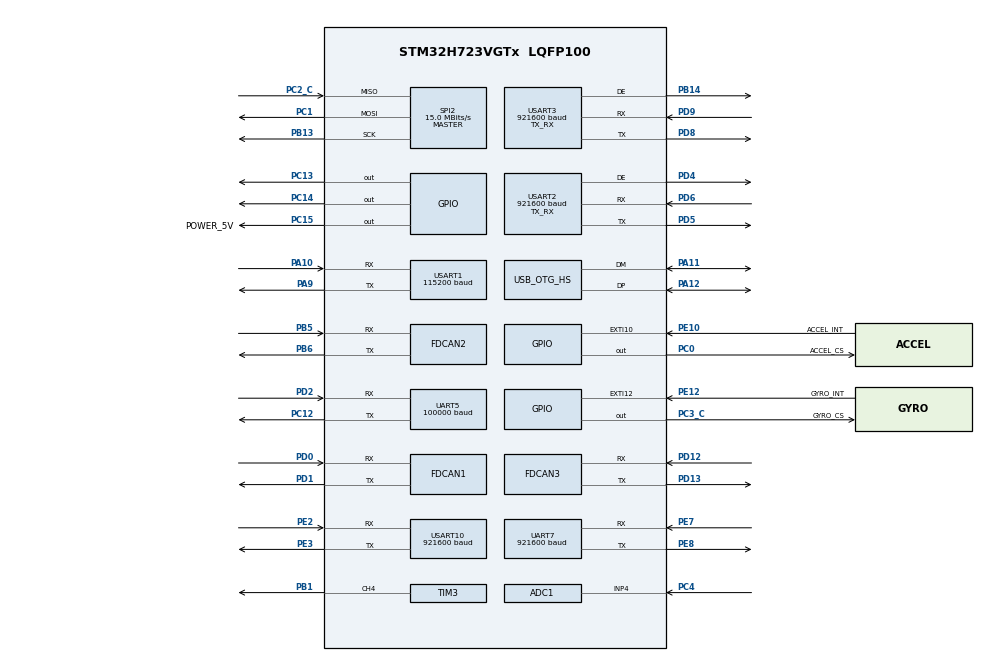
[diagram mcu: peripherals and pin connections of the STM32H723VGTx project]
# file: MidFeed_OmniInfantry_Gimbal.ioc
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ADC1.Channel-2\#ChannelRegularConversion=ADC_CHANNEL_4
ADC1.Channel-3\#ChannelRegularConversion=ADC_CHANNEL_4
ADC1.Channel-IN4=ADC_CHANNEL_4
ADC1.ClockPrescaler=ADC_CLOCK_ASYNC_DIV64
ADC1.ContinuousConvMode=ENABLE
ADC1.ConversionDataManagement=ADC_CONVERSIONDATA_DMA_CIRCULAR
ADC1.DiscontinuousConvMode=DISABLE
ADC1.EOCSelection=ADC_EOC_SINGLE_CONV
ADC1.EnableAnalogWatchDog1=false
ADC1.EnableAnalogWatchDog2=false
ADC1.EnableAnalogWatchDog3=false
ADC1.EnableInjectedConversion=DISABLE
ADC1.EnableRegularConversion=ENABLE
ADC1.ExternalTrigConv=ADC_SOFTWARE_START
ADC1.ExternalTrigConvEdge=ADC_EXTERNALTRIGCONVEDGE_NONE
ADC1.LeftBitShift=ADC_LEFTBITSHIFT_NONE
ADC1.LowPowerAutoWait=DISABLE
ADC1.Mode=ADC_MODE_INDEPENDENT
ADC1.NbrOfConversion=2
ADC1.OffsetNumber-2\#ChannelRegularConversion=ADC_OFFSET_NONE
ADC1.OffsetNumber-3\#ChannelRegularConversion=ADC_OFFSET_NONE
ADC1.OffsetSignedSaturation-2\#ChannelRegularConversion=DISABLE
ADC1.OffsetSignedSaturation-3\#ChannelRegularConversion=DISABLE
ADC1.Overrun=ADC_OVR_DATA_PRESERVED
ADC1.OversamplingMode=DISABLE
ADC1.Rank-2\#ChannelRegularConversion=1
ADC1.Rank-3\#ChannelRegularConversion=2
ADC1.Ratio=1
ADC1.Resolution=ADC_RESOLUTION_16B
ADC1.SamplingTime-2\#ChannelRegularConversion=ADC_SAMPLETIME_32CYCLES_5
ADC1.SamplingTime-3\#ChannelRegularConversion=ADC_SAMPLETIME_1CYCLE_5
ADC1.ScanConvMode=ADC_SCAN_ENABLE
ADC1.master=1
ADC3.Channel-0\#ChannelRegularConversion=ADC_CHANNEL_VBAT
ADC3.Channel-IN=ADC_CHANNEL_VREFINT
ADC3.ClockPrescaler=ADC_CLOCK_ASYNC_DIV64
ADC3.ClockPrescalerADC3=ADC_CLOCK_SYNC_PCLK_DIV4
ADC3.ContinuousConvMode=DISABLE
ADC3.ConversionDataManagement=ADC_CONVERSIONDATA_DR
ADC3.DMAContinuousRequests=DISABLE
ADC3.DataAlign=ADC3_DATAALIGN_RIGHT
ADC3.DiscontinuousConvMode=ENABLE
ADC3.EOCSelection=ADC_EOC_SINGLE_CONV
ADC3.EnableAnalogWatchDog1=false
ADC3.EnableAnalogWatchDog2=false
ADC3.EnableAnalogWatchDog3=false
ADC3.EnableInjectedConversion=DISABLE
ADC3.EnableRegularConversion=ENABLE
ADC3.ExternalTrigConv=ADC_SOFTWARE_START
ADC3.ExternalTrigConvEdge=ADC_EXTERNALTRIGCONVEDGE_NONE
ADC3.LeftBitShift=ADC_LEFTBITSHIFT_NONE
ADC3.LowPowerAutoWait=DISABLE
ADC3.NbrOfConversion=1
ADC3.NbrOfDiscConversion=1
ADC3.OffsetNumber-0\#ChannelRegularConversion=ADC_OFFSET_NONE
ADC3.OffsetSign-0\#ChannelRegularConversion=ADC3_OFFSET_SIGN_NEGATIVE
ADC3.Overrun=ADC_OVR_DATA_PRESERVED
ADC3.OversamplingMode=DISABLE
ADC3.Rank-0\#ChannelRegularConversion=1
ADC3.Ratio=ADC3_OVERSAMPLING_RATIO_2
ADC3.ResolutionADC3=ADC_RESOLUTION_12B
ADC3.SamplingMode=ADC_SAMPLING_MODE_NORMAL
ADC3.SamplingTime-0\#ChannelRegularConversion=ADC3_SAMPLETIME_2CYCLES_5
ADC3.ScanConvMode=ADC_SCAN_DISABLE
CORTEX_M7.default_mode_Activation=1
Dma.ADC1.1.Direction=DMA_PERIPH_TO_MEMORY
Dma.ADC1.1.EventEnable=DISABLE
Dma.ADC1.1.FIFOMode=DMA_FIFOMODE_DISABLE
Dma.ADC1.1.Instance=DMA2_Stream6
Dma.ADC1.1.MemDataAlignment=DMA_MDATAALIGN_HALFWORD
Dma.ADC1.1.MemInc=DMA_MINC_ENABLE
Dma.ADC1.1.Mode=DMA_CIRCULAR
Dma.ADC1.1.PeriphDataAlignment=DMA_PDATAALIGN_HALFWORD
Dma.ADC1.1.PeriphInc=DMA_PINC_DISABLE
Dma.ADC1.1.Polarity=HAL_DMAMUX_REQ_GEN_RISING
Dma.ADC1.1.Priority=DMA_PRIORITY_LOW
Dma.ADC1.1.RequestNumber=1
Dma.ADC1.1.SignalID=NONE
Dma.ADC1.1.SyncEnable=DISABLE
Dma.ADC1.1.SyncPolarity=HAL_DMAMUX_SYNC_NO_EVENT
Dma.ADC1.1.SyncRequestNumber=1
Dma.ADC1.1.SyncSignalID=NONE
Dma.ADC3.8.Direction=DMA_PERIPH_TO_MEMORY
Dma.ADC3.8.EventEnable=DISABLE
Dma.ADC3.8.FIFOMode=DMA_FIFOMODE_DISABLE
Dma.ADC3.8.Instance=DMA1_Stream0
Dma.ADC3.8.MemDataAlignment=DMA_MDATAALIGN_HALFWORD
Dma.ADC3.8.MemInc=DMA_MINC_ENABLE
Dma.ADC3.8.Mode=DMA_CIRCULAR
Dma.ADC3.8.PeriphDataAlignment=DMA_PDATAALIGN_HALFWORD
Dma.ADC3.8.PeriphInc=DMA_PINC_DISABLE
Dma.ADC3.8.Polarity=HAL_DMAMUX_REQ_GEN_RISING
Dma.ADC3.8.Priority=DMA_PRIORITY_LOW
Dma.ADC3.8.RequestNumber=1
Dma.ADC3.8.SignalID=NONE
Dma.ADC3.8.SyncEnable=DISABLE
Dma.ADC3.8.SyncPolarity=HAL_DMAMUX_SYNC_NO_EVENT
Dma.ADC3.8.SyncRequestNumber=1
Dma.ADC3.8.SyncSignalID=NONE
Dma.MEMTOMEM.15.Direction=DMA_MEMORY_TO_MEMORY
Dma.MEMTOMEM.15.EventEnable=DISABLE
Dma.MEMTOMEM.15.FIFOMode=DMA_FIFOMODE_DISABLE
Dma.MEMTOMEM.15.Instance=DMA2_Stream7
Dma.MEMTOMEM.15.MemDataAlignment=DMA_MDATAALIGN_BYTE
Dma.MEMTOMEM.15.MemInc=DMA_MINC_ENABLE
Dma.MEMTOMEM.15.Mode=DMA_NORMAL
Dma.MEMTOMEM.15.PeriphDataAlignment=DMA_PDATAALIGN_BYTE
Dma.MEMTOMEM.15.PeriphInc=DMA_PINC_ENABLE
Dma.MEMTOMEM.15.Polarity=HAL_DMAMUX_REQ_GEN_RISING
Dma.MEMTOMEM.15.Priority=DMA_PRIORITY_LOW
Dma.MEMTOMEM.15.RequestNumber=1
Dma.MEMTOMEM.15.SignalID=NONE
Dma.MEMTOMEM.15.SyncEnable=DISABLE
Dma.MEMTOMEM.15.SyncPolarity=HAL_DMAMUX_SYNC_NO_EVENT
Dma.MEMTOMEM.15.SyncRequestNumber=1
Dma.MEMTOMEM.15.SyncSignalID=NONE
Dma.Request0=UART5_RX
Dma.Request1=ADC1
Dma.Request10=USART2_TX
Dma.Request11=UART7_RX
Dma.Request12=UART7_TX
Dma.Request13=SPI2_RX
Dma.Request14=SPI2_TX
Dma.Request15=MEMTOMEM
Dma.Request2=USART1_RX
Dma.Request3=USART1_TX
Dma.Request4=USART10_RX
Dma.Request5=USART10_TX
Dma.Request6=USART3_RX
Dma.Request7=USART3_TX
Dma.Request8=ADC3
Dma.Request9=USART2_RX
Dma.SPI2_RX.13.Direction=DMA_PERIPH_TO_MEMORY
Dma.SPI2_RX.13.EventEnable=DISABLE
Dma.SPI2_RX.13.FIFOMode=DMA_FIFOMODE_DISABLE
Dma.SPI2_RX.13.Instance=DMA1_Stream1
Dma.SPI2_RX.13.MemDataAlignment=DMA_MDATAALIGN_BYTE
Dma.SPI2_RX.13.MemInc=DMA_MINC_ENABLE
Dma.SPI2_RX.13.Mode=DMA_NORMAL
Dma.SPI2_RX.13.PeriphDataAlignment=DMA_PDATAALIGN_BYTE
Dma.SPI2_RX.13.PeriphInc=DMA_PINC_DISABLE
Dma.SPI2_RX.13.Polarity=HAL_DMAMUX_REQ_GEN_RISING
Dma.SPI2_RX.13.Priority=DMA_PRIORITY_VERY_HIGH
Dma.SPI2_RX.13.RequestNumber=1
Dma.SPI2_RX.13.SignalID=NONE
Dma.SPI2_RX.13.SyncEnable=DISABLE
Dma.SPI2_RX.13.SyncPolarity=HAL_DMAMUX_SYNC_NO_EVENT
Dma.SPI2_RX.13.SyncRequestNumber=1
Dma.SPI2_RX.13.SyncSignalID=NONE
Dma.SPI2_TX.14.Direction=DMA_MEMORY_TO_PERIPH
Dma.SPI2_TX.14.EventEnable=DISABLE
Dma.SPI2_TX.14.FIFOMode=DMA_FIFOMODE_DISABLE
Dma.SPI2_TX.14.Instance=DMA1_Stream2
Dma.SPI2_TX.14.MemDataAlignment=DMA_MDATAALIGN_BYTE
Dma.SPI2_TX.14.MemInc=DMA_MINC_ENABLE
Dma.SPI2_TX.14.Mode=DMA_NORMAL
Dma.SPI2_TX.14.PeriphDataAlignment=DMA_PDATAALIGN_BYTE
Dma.SPI2_TX.14.PeriphInc=DMA_PINC_DISABLE
Dma.SPI2_TX.14.Polarity=HAL_DMAMUX_REQ_GEN_RISING
Dma.SPI2_TX.14.Priority=DMA_PRIORITY_MEDIUM
Dma.SPI2_TX.14.RequestNumber=1
Dma.SPI2_TX.14.SignalID=NONE
Dma.SPI2_TX.14.SyncEnable=DISABLE
Dma.SPI2_TX.14.SyncPolarity=HAL_DMAMUX_SYNC_NO_EVENT
Dma.SPI2_TX.14.SyncRequestNumber=1
Dma.SPI2_TX.14.SyncSignalID=NONE
Dma.UART5_RX.0.Direction=DMA_PERIPH_TO_MEMORY
Dma.UART5_RX.0.EventEnable=DISABLE
Dma.UART5_RX.0.FIFOMode=DMA_FIFOMODE_DISABLE
Dma.UART5_RX.0.Instance=DMA2_Stream3
Dma.UART5_RX.0.MemDataAlignment=DMA_MDATAALIGN_BYTE
Dma.UART5_RX.0.MemInc=DMA_MINC_ENABLE
Dma.UART5_RX.0.Mode=DMA_CIRCULAR
Dma.UART5_RX.0.PeriphDataAlignment=DMA_PDATAALIGN_BYTE
Dma.UART5_RX.0.PeriphInc=DMA_PINC_DISABLE
Dma.UART5_RX.0.Polarity=HAL_DMAMUX_REQ_GEN_RISING
Dma.UART5_RX.0.Priority=DMA_PRIORITY_VERY_HIGH
Dma.UART5_RX.0.RequestNumber=1
Dma.UART5_RX.0.SignalID=NONE
Dma.UART5_RX.0.SyncEnable=DISABLE
Dma.UART5_RX.0.SyncPolarity=HAL_DMAMUX_SYNC_NO_EVENT
Dma.UART5_RX.0.SyncRequestNumber=1
Dma.UART5_RX.0.SyncSignalID=NONE
Dma.UART7_RX.11.Direction=DMA_PERIPH_TO_MEMORY
Dma.UART7_RX.11.EventEnable=DISABLE
Dma.UART7_RX.11.FIFOMode=DMA_FIFOMODE_DISABLE
Dma.UART7_RX.11.Instance=DMA1_Stream3
Dma.UART7_RX.11.MemDataAlignment=DMA_MDATAALIGN_BYTE
Dma.UART7_RX.11.MemInc=DMA_MINC_ENABLE
Dma.UART7_RX.11.Mode=DMA_CIRCULAR
Dma.UART7_RX.11.PeriphDataAlignment=DMA_PDATAALIGN_BYTE
Dma.UART7_RX.11.PeriphInc=DMA_PINC_DISABLE
Dma.UART7_RX.11.Polarity=HAL_DMAMUX_REQ_GEN_RISING
Dma.UART7_RX.11.Priority=DMA_PRIORITY_LOW
Dma.UART7_RX.11.RequestNumber=1
Dma.UART7_RX.11.SignalID=NONE
Dma.UART7_RX.11.SyncEnable=DISABLE
Dma.UART7_RX.11.SyncPolarity=HAL_DMAMUX_SYNC_NO_EVENT
Dma.UART7_RX.11.SyncRequestNumber=1
Dma.UART7_RX.11.SyncSignalID=NONE
Dma.UART7_TX.12.Direction=DMA_MEMORY_TO_PERIPH
Dma.UART7_TX.12.EventEnable=DISABLE
Dma.UART7_TX.12.FIFOMode=DMA_FIFOMODE_DISABLE
Dma.UART7_TX.12.Instance=DMA1_Stream4
Dma.UART7_TX.12.MemDataAlignment=DMA_MDATAALIGN_BYTE
Dma.UART7_TX.12.MemInc=DMA_MINC_ENABLE
Dma.UART7_TX.12.Mode=DMA_NORMAL
Dma.UART7_TX.12.PeriphDataAlignment=DMA_PDATAALIGN_BYTE
Dma.UART7_TX.12.PeriphInc=DMA_PINC_DISABLE
Dma.UART7_TX.12.Polarity=HAL_DMAMUX_REQ_GEN_RISING
Dma.UART7_TX.12.Priority=DMA_PRIORITY_LOW
Dma.UART7_TX.12.RequestNumber=1
Dma.UART7_TX.12.SignalID=NONE
Dma.UART7_TX.12.SyncEnable=DISABLE
Dma.UART7_TX.12.SyncPolarity=HAL_DMAMUX_SYNC_NO_EVENT
Dma.UART7_TX.12.SyncRequestNumber=1
Dma.UART7_TX.12.SyncSignalID=NONE
Dma.USART10_RX.4.Direction=DMA_PERIPH_TO_MEMORY
Dma.USART10_RX.4.EventEnable=DISABLE
Dma.USART10_RX.4.FIFOMode=DMA_FIFOMODE_DISABLE
Dma.USART10_RX.4.Instance=DMA2_Stream4
Dma.USART10_RX.4.MemDataAlignment=DMA_MDATAALIGN_BYTE
Dma.USART10_RX.4.MemInc=DMA_MINC_ENABLE
Dma.USART10_RX.4.Mode=DMA_CIRCULAR
Dma.USART10_RX.4.PeriphDataAlignment=DMA_PDATAALIGN_BYTE
Dma.USART10_RX.4.PeriphInc=DMA_PINC_DISABLE
Dma.USART10_RX.4.Polarity=HAL_DMAMUX_REQ_GEN_RISING
Dma.USART10_RX.4.Priority=DMA_PRIORITY_VERY_HIGH
Dma.USART10_RX.4.RequestNumber=1
Dma.USART10_RX.4.SignalID=NONE
Dma.USART10_RX.4.SyncEnable=DISABLE
Dma.USART10_RX.4.SyncPolarity=HAL_DMAMUX_SYNC_NO_EVENT
Dma.USART10_RX.4.SyncRequestNumber=1
Dma.USART10_RX.4.SyncSignalID=NONE
Dma.USART10_TX.5.Direction=DMA_MEMORY_TO_PERIPH
Dma.USART10_TX.5.EventEnable=DISABLE
Dma.USART10_TX.5.FIFOMode=DMA_FIFOMODE_DISABLE
Dma.USART10_TX.5.Instance=DMA2_Stream5
Dma.USART10_TX.5.MemDataAlignment=DMA_MDATAALIGN_BYTE
Dma.USART10_TX.5.MemInc=DMA_MINC_ENABLE
Dma.USART10_TX.5.Mode=DMA_NORMAL
Dma.USART10_TX.5.PeriphDataAlignment=DMA_PDATAALIGN_BYTE
Dma.USART10_TX.5.PeriphInc=DMA_PINC_DISABLE
Dma.USART10_TX.5.Polarity=HAL_DMAMUX_REQ_GEN_RISING
Dma.USART10_TX.5.Priority=DMA_PRIORITY_VERY_HIGH
Dma.USART10_TX.5.RequestNumber=1
Dma.USART10_TX.5.SignalID=NONE
Dma.USART10_TX.5.SyncEnable=DISABLE
Dma.USART10_TX.5.SyncPolarity=HAL_DMAMUX_SYNC_NO_EVENT
Dma.USART10_TX.5.SyncRequestNumber=1
Dma.USART10_TX.5.SyncSignalID=NONE
Dma.USART1_RX.2.Direction=DMA_PERIPH_TO_MEMORY
Dma.USART1_RX.2.EventEnable=DISABLE
Dma.USART1_RX.2.FIFOMode=DMA_FIFOMODE_DISABLE
Dma.USART1_RX.2.Instance=DMA1_Stream5
Dma.USART1_RX.2.MemDataAlignment=DMA_MDATAALIGN_BYTE
Dma.USART1_RX.2.MemInc=DMA_MINC_ENABLE
Dma.USART1_RX.2.Mode=DMA_NORMAL
Dma.USART1_RX.2.PeriphDataAlignment=DMA_PDATAALIGN_BYTE
Dma.USART1_RX.2.PeriphInc=DMA_PINC_DISABLE
Dma.USART1_RX.2.Polarity=HAL_DMAMUX_REQ_GEN_RISING
Dma.USART1_RX.2.Priority=DMA_PRIORITY_VERY_HIGH
Dma.USART1_RX.2.RequestNumber=1
Dma.USART1_RX.2.SignalID=NONE
Dma.USART1_RX.2.SyncEnable=DISABLE
Dma.USART1_RX.2.SyncPolarity=HAL_DMAMUX_SYNC_NO_EVENT
Dma.USART1_RX.2.SyncRequestNumber=1
Dma.USART1_RX.2.SyncSignalID=NONE
Dma.USART1_TX.3.Direction=DMA_MEMORY_TO_PERIPH
Dma.USART1_TX.3.EventEnable=DISABLE
Dma.USART1_TX.3.FIFOMode=DMA_FIFOMODE_DISABLE
Dma.USART1_TX.3.Instance=DMA1_Stream6
Dma.USART1_TX.3.MemDataAlignment=DMA_MDATAALIGN_BYTE
Dma.USART1_TX.3.MemInc=DMA_MINC_ENABLE
Dma.USART1_TX.3.Mode=DMA_NORMAL
Dma.USART1_TX.3.PeriphDataAlignment=DMA_PDATAALIGN_BYTE
Dma.USART1_TX.3.PeriphInc=DMA_PINC_DISABLE
Dma.USART1_TX.3.Polarity=HAL_DMAMUX_REQ_GEN_RISING
Dma.USART1_TX.3.Priority=DMA_PRIORITY_VERY_HIGH
Dma.USART1_TX.3.RequestNumber=1
Dma.USART1_TX.3.SignalID=NONE
Dma.USART1_TX.3.SyncEnable=DISABLE
Dma.USART1_TX.3.SyncPolarity=HAL_DMAMUX_SYNC_NO_EVENT
Dma.USART1_TX.3.SyncRequestNumber=1
Dma.USART1_TX.3.SyncSignalID=NONE
Dma.USART2_RX.9.Direction=DMA_PERIPH_TO_MEMORY
Dma.USART2_RX.9.EventEnable=DISABLE
Dma.USART2_RX.9.FIFOMode=DMA_FIFOMODE_DISABLE
Dma.USART2_RX.9.Instance=DMA1_Stream7
Dma.USART2_RX.9.MemDataAlignment=DMA_MDATAALIGN_BYTE
Dma.USART2_RX.9.MemInc=DMA_MINC_ENABLE
Dma.USART2_RX.9.Mode=DMA_CIRCULAR
Dma.USART2_RX.9.PeriphDataAlignment=DMA_PDATAALIGN_BYTE
Dma.USART2_RX.9.PeriphInc=DMA_PINC_DISABLE
Dma.USART2_RX.9.Polarity=HAL_DMAMUX_REQ_GEN_RISING
Dma.USART2_RX.9.Priority=DMA_PRIORITY_MEDIUM
Dma.USART2_RX.9.RequestNumber=1
Dma.USART2_RX.9.SignalID=NONE
Dma.USART2_RX.9.SyncEnable=DISABLE
Dma.USART2_RX.9.SyncPolarity=HAL_DMAMUX_SYNC_NO_EVENT
Dma.USART2_RX.9.SyncRequestNumber=1
Dma.USART2_RX.9.SyncSignalID=NONE
Dma.USART2_TX.10.Direction=DMA_MEMORY_TO_PERIPH
Dma.USART2_TX.10.EventEnable=DISABLE
Dma.USART2_TX.10.FIFOMode=DMA_FIFOMODE_DISABLE
Dma.USART2_TX.10.Instance=DMA2_Stream0
Dma.USART2_TX.10.MemDataAlignment=DMA_MDATAALIGN_BYTE
Dma.USART2_TX.10.MemInc=DMA_MINC_ENABLE
Dma.USART2_TX.10.Mode=DMA_NORMAL
Dma.USART2_TX.10.PeriphDataAlignment=DMA_PDATAALIGN_BYTE
Dma.USART2_TX.10.PeriphInc=DMA_PINC_DISABLE
Dma.USART2_TX.10.Polarity=HAL_DMAMUX_REQ_GEN_RISING
Dma.USART2_TX.10.Priority=DMA_PRIORITY_MEDIUM
Dma.USART2_TX.10.RequestNumber=1
Dma.USART2_TX.10.SignalID=NONE
Dma.USART2_TX.10.SyncEnable=DISABLE
Dma.USART2_TX.10.SyncPolarity=HAL_DMAMUX_SYNC_NO_EVENT
Dma.USART2_TX.10.SyncRequestNumber=1
Dma.USART2_TX.10.SyncSignalID=NONE
Dma.USART3_RX.6.Direction=DMA_PERIPH_TO_MEMORY
Dma.USART3_RX.6.EventEnable=DISABLE
Dma.USART3_RX.6.FIFOMode=DMA_FIFOMODE_DISABLE
Dma.USART3_RX.6.Instance=DMA2_Stream1
Dma.USART3_RX.6.MemDataAlignment=DMA_MDATAALIGN_BYTE
Dma.USART3_RX.6.MemInc=DMA_MINC_ENABLE
Dma.USART3_RX.6.Mode=DMA_CIRCULAR
Dma.USART3_RX.6.PeriphDataAlignment=DMA_PDATAALIGN_BYTE
Dma.USART3_RX.6.PeriphInc=DMA_PINC_DISABLE
Dma.USART3_RX.6.Polarity=HAL_DMAMUX_REQ_GEN_RISING
Dma.USART3_RX.6.Priority=DMA_PRIORITY_MEDIUM
Dma.USART3_RX.6.RequestNumber=1
Dma.USART3_RX.6.SignalID=NONE
Dma.USART3_RX.6.SyncEnable=DISABLE
Dma.USART3_RX.6.SyncPolarity=HAL_DMAMUX_SYNC_NO_EVENT
Dma.USART3_RX.6.SyncRequestNumber=1
Dma.USART3_RX.6.SyncSignalID=NONE
Dma.USART3_TX.7.Direction=DMA_MEMORY_TO_PERIPH
Dma.USART3_TX.7.EventEnable=DISABLE
Dma.USART3_TX.7.FIFOMode=DMA_FIFOMODE_DISABLE
Dma.USART3_TX.7.Instance=DMA2_Stream2
Dma.USART3_TX.7.MemDataAlignment=DMA_MDATAALIGN_BYTE
Dma.USART3_TX.7.MemInc=DMA_MINC_ENABLE
Dma.USART3_TX.7.Mode=DMA_NORMAL
Dma.USART3_TX.7.PeriphDataAlignment=DMA_PDATAALIGN_BYTE
Dma.USART3_TX.7.PeriphInc=DMA_PINC_DISABLE
Dma.USART3_TX.7.Polarity=HAL_DMAMUX_REQ_GEN_RISING
Dma.USART3_TX.7.Priority=DMA_PRIORITY_MEDIUM
Dma.USART3_TX.7.RequestNumber=1
Dma.USART3_TX.7.SignalID=NONE
Dma.USART3_TX.7.SyncEnable=DISABLE
Dma.USART3_TX.7.SyncPolarity=HAL_DMAMUX_SYNC_NO_EVENT
Dma.USART3_TX.7.SyncRequestNumber=1
Dma.USART3_TX.7.SyncSignalID=NONE
FDCAN1.AutoRetransmission=DISABLE
FDCAN1.CalculateBaudRateNominal=1000000
FDCAN1.CalculateTimeBitNominal=1000
FDCAN1.CalculateTimeQuantumNominal=25.0
FDCAN1.ClockCalibrationCCU=DISABLE
FDCAN1.DataPrescaler=3
FDCAN1.DataSyncJumpWidth=10
FDCAN1.DataTimeSeg1=29
FDCAN1.DataTimeSeg2=10
FDCAN1.ExtFiltersNbr=0
FDCAN1.FrameFormat=FDCAN_FRAME_CLASSIC
FDCAN1.MessageRAMOffset=0
FDCAN1.Mode=FDCAN_MODE_NORMAL
FDCAN1.NominalPrescaler=3
FDCAN1.NominalSyncJumpWidth=10
FDCAN1.NominalTimeSeg1=29
FDCAN1.NominalTimeSeg2=10
FDCAN1.ProtocolException=ENABLE
FDCAN1.RxBufferSize=FDCAN_DATA_BYTES_8
FDCAN1.RxBuffersNbr=0
FDCAN1.RxFifo0ElmtSize=FDCAN_DATA_BYTES_8
FDCAN1.RxFifo0ElmtsNbr=8
FDCAN1.RxFifo1ElmtSize=FDCAN_DATA_BYTES_8
FDCAN1.RxFifo1ElmtsNbr=8
FDCAN1.StdFiltersNbr=1
FDCAN1.TransmitPause=DISABLE
FDCAN1.TxBuffersNbr=0
FDCAN1.TxElmtSize=FDCAN_DATA_BYTES_8
FDCAN1.TxEventsNbr=0
FDCAN1.TxFifoQueueElmtsNbr=8
FDCAN1.TxFifoQueueMode=FDCAN_TX_FIFO_OPERATION
FDCAN2.AutoRetransmission=DISABLE
FDCAN2.CalculateBaudRateNominal=1000000
FDCAN2.CalculateTimeBitNominal=1000
FDCAN2.CalculateTimeQuantumNominal=25.0
FDCAN2.ClockCalibrationCCU=DISABLE
FDCAN2.DataPrescaler=3
FDCAN2.DataSyncJumpWidth=10
FDCAN2.DataTimeSeg1=29
FDCAN2.DataTimeSeg2=10
FDCAN2.ExtFiltersNbr=0
FDCAN2.FrameFormat=FDCAN_FRAME_CLASSIC
FDCAN2.MessageRAMOffset=853
FDCAN2.Mode=FDCAN_MODE_NORMAL
FDCAN2.NominalPrescaler=3
FDCAN2.NominalSyncJumpWidth=10
FDCAN2.NominalTimeSeg1=29
FDCAN2.NominalTimeSeg2=10
FDCAN2.ProtocolException=ENABLE
FDCAN2.RxBufferSize=FDCAN_DATA_BYTES_8
FDCAN2.RxBuffersNbr=0
FDCAN2.RxFifo0ElmtSize=FDCAN_DATA_BYTES_8
FDCAN2.RxFifo0ElmtsNbr=8
FDCAN2.RxFifo1ElmtSize=FDCAN_DATA_BYTES_8
FDCAN2.RxFifo1ElmtsNbr=8
FDCAN2.StdFiltersNbr=1
FDCAN2.TransmitPause=DISABLE
FDCAN2.TxBuffersNbr=0
FDCAN2.TxElmtSize=FDCAN_DATA_BYTES_8
FDCAN2.TxEventsNbr=0
FDCAN2.TxFifoQueueElmtsNbr=8
FDCAN2.TxFifoQueueMode=FDCAN_TX_FIFO_OPERATION
FDCAN3.AutoRetransmission=DISABLE
FDCAN3.CalculateBaudRateNominal=1000000
FDCAN3.CalculateTimeBitNominal=1000
FDCAN3.CalculateTimeQuantumNominal=25.0
FDCAN3.ClockCalibrationCCU=DISABLE
FDCAN3.DataPrescaler=3
FDCAN3.DataSyncJumpWidth=10
FDCAN3.DataTimeSeg1=29
FDCAN3.DataTimeSeg2=10
FDCAN3.ExtFiltersNbr=0
FDCAN3.FrameFormat=FDCAN_FRAME_CLASSIC
FDCAN3.MessageRAMOffset=1706
FDCAN3.Mode=FDCAN_MODE_NORMAL
FDCAN3.NominalPrescaler=3
FDCAN3.NominalSyncJumpWidth=10
FDCAN3.NominalTimeSeg1=29
FDCAN3.NominalTimeSeg2=10
FDCAN3.ProtocolException=ENABLE
FDCAN3.RxBufferSize=FDCAN_DATA_BYTES_8
FDCAN3.RxBuffersNbr=0
FDCAN3.RxFifo0ElmtSize=FDCAN_DATA_BYTES_8
FDCAN3.RxFifo0ElmtsNbr=8
FDCAN3.RxFifo1ElmtSize=FDCAN_DATA_BYTES_8
FDCAN3.RxFifo1ElmtsNbr=8
FDCAN3.StdFiltersNbr=1
FDCAN3.TransmitPause=DISABLE
FDCAN3.TxBuffersNbr=0
FDCAN3.TxElmtSize=FDCAN_DATA_BYTES_8
FDCAN3.TxEventsNbr=0
FDCAN3.TxFifoQueueElmtsNbr=8
FDCAN3.TxFifoQueueMode=FDCAN_TX_FIFO_OPERATION
FREERTOS.HEAP_NUMBER=4
FREERTOS.INCLUDE_eTaskGetState=0
FREERTOS.INCLUDE_pcTaskGetTaskName=0
FREERTOS.INCLUDE_uxTaskGetStackHighWaterMark=0
FREERTOS.INCLUDE_uxTaskGetStackHighWaterMark2=0
FREERTOS.INCLUDE_uxTaskPriorityGet=1
FREERTOS.INCLUDE_vTaskCleanUpResources=0
FREERTOS.INCLUDE_vTaskDelay=1
FREERTOS.INCLUDE_vTaskDelayUntil=1
FREERTOS.INCLUDE_vTaskDelete=1
FREERTOS.INCLUDE_vTaskPrioritySet=1
FREERTOS.INCLUDE_vTaskSuspend=1
FREERTOS.INCLUDE_xEventGroupSetBitFromISR=0
FREERTOS.INCLUDE_xQueueGetMutexHolder=0
FREERTOS.INCLUDE_xSemaphoreGetMutexHolder=0
FREERTOS.INCLUDE_xTaskAbortDelay=0
FREERTOS.INCLUDE_xTaskGetCurrentTaskHandle=0
FREERTOS.INCLUDE_xTaskGetHandle=0
FREERTOS.INCLUDE_xTaskResumeFromISR=1
FREERTOS.MEMORY_ALLOCATION=2
FREERTOS.Tasks01=Start_INS_Task,2,2048,INS_Task,As weak,NULL,Static,Start_INS_TaskBuffer,Start_INS_TaskControlBlock;Start_Control_Task,1,2048,Control_Task,As weak,NULL,Static,Start_Control_TaskBuffer,Start_Control_TaskControlBlock;Start_CAN_Task,0,2048,CAN_Task,As weak,NULL,Static,Start_CAN_TaskBuffer,Start_CAN_TaskControlBlock;Start_Detect_Task,-1,2048,Detect_Task,As weak,NULL,Static,Start_Detect_TaskBuffer,Start_Detect_TaskControlBlock
FREERTOS.configCHECK_FOR_STACK_OVERFLOW=0
FREERTOS.configENABLE_BACKWARD_COMPATIBILITY=1
FREERTOS.configENABLE_FPU=0
FREERTOS.configGENERATE_RUN_TIME_STATS=0
FREERTOS.configIDLE_SHOULD_YIELD=1
FREERTOS.configLIBRARY_LOWEST_INTERRUPT_PRIORITY=15
FREERTOS.configLIBRARY_MAX_SYSCALL_INTERRUPT_PRIORITY=5
FREERTOS.configMAX_CO_ROUTINE_PRIORITIES=2
FREERTOS.configMAX_PRIORITIES=7
FREERTOS.configMAX_TASK_NAME_LEN=64
FREERTOS.configMINIMAL_STACK_SIZE=2048
FREERTOS.configQUEUE_REGISTRY_SIZE=8
FREERTOS.configRECORD_STACK_HIGH_ADDRESS=0
FREERTOS.configTICK_RATE_HZ=1000
FREERTOS.configTOTAL_HEAP_SIZE=15360
FREERTOS.configUSE_APPLICATION_TASK_TAG=0
FREERTOS.configUSE_COUNTING_SEMAPHORES=0
FREERTOS.configUSE_CO_ROUTINES=0
FREERTOS.configUSE_DAEMON_TASK_STARTUP_HOOK=0
FREERTOS.configUSE_IDLE_HOOK=0
FREERTOS.configUSE_MALLOC_FAILED_HOOK=0
FREERTOS.configUSE_MUTEXES=1
FREERTOS.configUSE_NEWLIB_REENTRANT=1
FREERTOS.configUSE_POSIX_ERRNO=0
FREERTOS.configUSE_PREEMPTION=1
FREERTOS.configUSE_RECURSIVE_MUTEXES=0
FREERTOS.configUSE_STATS_FORMATTING_FUNCTIONS=0
FREERTOS.configUSE_TASK_NOTIFICATIONS=1
FREERTOS.configUSE_TICKLESS_IDLE=0
FREERTOS.configUSE_TICK_HOOK=0
FREERTOS.configUSE_TIMERS=0
FREERTOS.configUSE_TRACE_FACILITY=1
FREERTOS.copyHeapFile=1
Mcu.Family=STM32H7
Mcu.Name=STM32H723VGTx
Mcu.Package=LQFP100
NVIC.DMA1_Stream0_IRQn=true\:5\:0\:false\:false\:true\:true\:false\:true\:true
NVIC.DMA1_Stream1_IRQn=true\:5\:0\:false\:false\:true\:true\:false\:true\:true
NVIC.DMA1_Stream2_IRQn=true\:5\:0\:false\:false\:true\:true\:false\:true\:true
NVIC.DMA1_Stream3_IRQn=true\:5\:0\:false\:false\:true\:true\:false\:true\:true
NVIC.DMA1_Stream4_IRQn=true\:5\:0\:false\:false\:true\:true\:false\:true\:true
NVIC.DMA1_Stream5_IRQn=true\:5\:0\:false\:false\:true\:true\:false\:true\:true
NVIC.DMA1_Stream6_IRQn=true\:5\:0\:false\:false\:true\:true\:false\:true\:true
NVIC.DMA1_Stream7_IRQn=true\:5\:0\:false\:false\:true\:true\:false\:true\:true
NVIC.DMA2_Stream0_IRQn=true\:5\:0\:false\:false\:true\:true\:false\:true\:true
NVIC.DMA2_Stream1_IRQn=true\:5\:0\:false\:false\:true\:true\:false\:true\:true
NVIC.DMA2_Stream2_IRQn=true\:5\:0\:false\:false\:true\:true\:false\:true\:true
NVIC.DMA2_Stream3_IRQn=true\:5\:0\:false\:false\:true\:true\:false\:true\:true
NVIC.DMA2_Stream4_IRQn=true\:5\:0\:false\:false\:true\:true\:false\:true\:true
NVIC.DMA2_Stream5_IRQn=true\:5\:0\:false\:false\:true\:true\:false\:true\:true
NVIC.DMA2_Stream6_IRQn=true\:5\:0\:false\:false\:true\:true\:false\:true\:true
NVIC.DMA2_Stream7_IRQn=true\:5\:0\:false\:false\:true\:true\:false\:true\:true
NVIC.FDCAN1_IT0_IRQn=true\:5\:0\:false\:false\:true\:true\:true\:true\:true
NVIC.FDCAN1_IT1_IRQn=true\:5\:0\:false\:false\:true\:true\:true\:true\:true
NVIC.FDCAN2_IT0_IRQn=true\:5\:0\:false\:false\:true\:true\:true\:true\:true
NVIC.FDCAN2_IT1_IRQn=true\:5\:0\:false\:false\:true\:true\:true\:true\:true
NVIC.FDCAN3_IT0_IRQn=true\:5\:0\:false\:false\:true\:true\:true\:true\:true
NVIC.FDCAN3_IT1_IRQn=true\:5\:0\:false\:false\:true\:true\:true\:true\:true
NVIC.OTG_HS_IRQn=true\:5\:0\:false\:false\:true\:true\:true\:true\:true
NVIC.PriorityGroup=NVIC_PRIORITYGROUP_4
NVIC.SPI2_IRQn=true\:5\:0\:true\:false\:true\:true\:false\:true\:true
NVIC.TIM2_IRQn=true\:15\:0\:false\:false\:true\:false\:true\:true\:true
NVIC.TimeBase=TIM2_IRQn
NVIC.TimeBaseIP=TIM2
NVIC.UART5_IRQn=true\:5\:0\:false\:false\:true\:true\:true\:true\:true
NVIC.UART7_IRQn=true\:5\:0\:false\:false\:true\:true\:true\:true\:true
NVIC.USART10_IRQn=true\:5\:0\:false\:false\:true\:true\:true\:true\:true
NVIC.USART1_IRQn=true\:5\:0\:false\:false\:true\:true\:true\:true\:true
NVIC.USART2_IRQn=true\:5\:0\:false\:false\:true\:true\:true\:true\:true
NVIC.USART3_IRQn=true\:5\:0\:false\:false\:true\:true\:true\:true\:true
PA10.Mode=Asynchronous
PA10.Signal=USART1_RX
PA11.Mode=Device_Only_FS
PA11.Signal=USB_OTG_HS_DM
PA12.Mode=Device_Only_FS
PA12.Signal=USB_OTG_HS_DP
PA13(JTMS/SWDIO).Mode=Serial_Wire
PA13(JTMS/SWDIO).Signal=DEBUG_JTMS-SWDIO
PA14(JTCK/SWCLK).Mode=Serial_Wire
PA14(JTCK/SWCLK).Signal=DEBUG_JTCK-SWCLK
PA9.Mode=Asynchronous
PA9.Signal=USART1_TX
PB1.Signal=S_TIM3_CH4
PB13.GPIO_Speed=GPIO_SPEED_FREQ_VERY_HIGH
PB13.Mode=Full_Duplex_Master
PB13.Signal=SPI2_SCK
PB14.Mode=Hardware Flow Control (RS485)
PB14.Signal=USART3_DE
PB5.Mode=FDCAN_Activate
PB5.Signal=FDCAN2_RX
PB6.GPIO_FM6=__NULL
PB6.Mode=FDCAN_Activate
PB6.Signal=FDCAN2_TX
PC0.GPIO_Label=ACCEL_CS
PC0.GPIO_PuPd=GPIO_NOPULL
PC0.GPIO_Speed=GPIO_SPEED_FREQ_MEDIUM
PC0.PinState=GPIO_PIN_SET
PC0.Signal=GPIO_Output
PC1.GPIO_Speed=GPIO_SPEED_FREQ_VERY_HIGH
PC1.Mode=Full_Duplex_Master
PC1.Signal=SPI2_MOSI
PC12.Mode=Asynchronous
PC12.Signal=UART5_TX
PC13.PinState=GPIO_PIN_RESET
PC13.Signal=GPIO_Output
PC14-OSC32_IN.Signal=GPIO_Output
PC15-OSC32_OUT.GPIO_Label=POWER_5V
PC15-OSC32_OUT.PinState=GPIO_PIN_SET
PC15-OSC32_OUT.Signal=GPIO_Output
PC2_C.GPIO_Speed=GPIO_SPEED_FREQ_VERY_HIGH
PC2_C.Mode=Full_Duplex_Master
PC2_C.Signal=SPI2_MISO
PC3_C.GPIO_Label=GYRO_CS
PC3_C.GPIO_PuPd=GPIO_NOPULL
PC3_C.GPIO_Speed=GPIO_SPEED_FREQ_MEDIUM
PC3_C.PinState=GPIO_PIN_SET
PC3_C.Signal=GPIO_Output
PC4.Signal=ADCx_INP4
PD0.Mode=FDCAN_Activate
PD0.Signal=FDCAN1_RX
PD1.Mode=FDCAN_Activate
PD1.Signal=FDCAN1_TX
PD12.Mode=FDCAN_Activate
PD12.Signal=FDCAN3_RX
PD13.Mode=FDCAN_Activate
PD13.Signal=FDCAN3_TX
PD2.GPIO_Speed=GPIO_SPEED_FREQ_VERY_HIGH
PD2.Mode=Asynchronous
PD2.Signal=UART5_RX
PD4.Mode=Hardware Flow Control (RS485)
PD4.Signal=USART2_DE
PD5.Mode=Asynchronous
PD5.Signal=USART2_TX
PD6.Mode=Asynchronous
PD6.Signal=USART2_RX
PD8.Mode=Asynchronous
PD8.Signal=USART3_TX
PD9.Mode=Asynchronous
PD9.Signal=USART3_RX
PE10.GPIO_Label=ACCEL_INT
PE10.GPIO_PuPd=GPIO_NOPULL
PE10.Signal=GPXTI10
PE12.GPIO_Label=GYRO_INT
PE12.GPIO_PuPd=GPIO_NOPULL
PE12.Signal=GPXTI12
PE2.Mode=Asynchronous
PE2.Signal=USART10_RX
PE3.Mode=Asynchronous
PE3.Signal=USART10_TX
PE7.Mode=Asynchronous
PE7.Signal=UART7_RX
PE8.Mode=Asynchronous
PE8.Signal=UART7_TX
PH0-OSC_IN.Mode=HSE-External-Oscillator
PH0-OSC_IN.Signal=RCC_OSC_IN
PH1-OSC_OUT.Mode=HSE-External-Oscillator
PH1-OSC_OUT.Signal=RCC_OSC_OUT
ProjectManager.HeapSize=0x2000
ProjectManager.StackSize=0x4000
ProjectManager.TargetToolchain=STM32CubeIDE
RCC.ADCFreq_Value=96000000
RCC.APB1Freq_Value=120000000
RCC.APB2Freq_Value=120000000
RCC.APB3Freq_Value=120000000
RCC.APB4Freq_Value=120000000
RCC.CortexFreq_Value=480000000
RCC.D1PPRE=RCC_APB3_DIV2
RCC.D2PPRE1=RCC_APB1_DIV2
RCC.D2PPRE2=RCC_APB2_DIV2
RCC.D3PPRE=RCC_APB4_DIV2
RCC.DIVM1=2
RCC.DIVM2=2
RCC.DIVN1=40
RCC.DIVN2=32
RCC.DIVP1=1
RCC.DIVP2=4
RCC.DIVQ1=4
RCC.HCLKFreq_Value=240000000
RCC.HPRE=RCC_HCLK_DIV2
RCC.HSE_VALUE=24000000
RCC.PLL2FRACN=0
RCC.PLL2_VCO_SEL-AdvancedSettings=RCC_PLL2VCOMEDIUM
RCC.PLL3_VCO_SEL-AdvancedSettings=RCC_PLL3VCOWIDE
RCC.PLLFRACN=0
RCC.PLLSourceVirtual=RCC_PLLSOURCE_HSE
RCC.SYSCLKFreq_VALUE=480000000
RCC.SYSCLKSource=RCC_SYSCLKSOURCE_PLLCLK
RCC.USBFreq_Value=120000000
SH.ADCx_INP4.0=ADC1_INP4,IN4-Single-Ended
SH.S_TIM3_CH4.0=TIM3_CH4,PWM Generation4 CH4
SPI2.BaudRatePrescaler=SPI_BAUDRATEPRESCALER_8
SPI2.CLKPhase=SPI_PHASE_2EDGE
SPI2.CLKPolarity=SPI_POLARITY_HIGH
SPI2.CRCCalculation=SPI_CRCCALCULATION_DISABLE
SPI2.CalculateBaudRate=15.0 MBits/s
SPI2.DataSize=SPI_DATASIZE_8BIT
SPI2.Direction=SPI_DIRECTION_2LINES
SPI2.FifoThreshold=SPI_FIFO_THRESHOLD_01DATA
SPI2.FirstBit=SPI_FIRSTBIT_MSB
SPI2.IOSwap=SPI_IO_SWAP_DISABLE
SPI2.MasterInterDataIdleness=SPI_MASTER_INTERDATA_IDLENESS_00CYCLE
SPI2.MasterKeepIOState=SPI_MASTER_KEEP_IO_STATE_DISABLE
SPI2.MasterReceiverAutoSusp=SPI_MASTER_RX_AUTOSUSP_DISABLE
SPI2.MasterSSIdleness=SPI_MASTER_SS_IDLENESS_00CYCLE
SPI2.Mode=SPI_MODE_MASTER
SPI2.NSS=SPI_NSS_SOFT
SPI2.NSSPMode=SPI_NSS_PULSE_DISABLE
SPI2.NSSPolarity=SPI_NSS_POLARITY_LOW
SPI2.RxCRCInitializationPattern=SPI_CRC_INITIALIZATION_ALL_ZERO_PATTERN
SPI2.TIMode=SPI_TIMODE_DISABLE
SPI2.TxCRCInitializationPattern=SPI_CRC_INITIALIZATION_ALL_ZERO_PATTERN
SPI2.VirtualType=VM_MASTER
TIM3.AutoReloadPreload=TIM_AUTORELOAD_PRELOAD_ENABLE
TIM3.Channel-PWM\ Generation4\ CH4=TIM_CHANNEL_4
TIM3.ClearInputSource=TIM_CLEARINPUTSOURCE_NONE
TIM3.ClockDivision=TIM_CLOCKDIVISION_DIV1
TIM3.CounterMode=TIM_COUNTERMODE_UP
TIM3.OC4Preload_PWM=ENABLE
TIM3.OCFastMode_PWM-PWM\ Generation4\ CH4=TIM_OCFAST_DISABLE
TIM3.OCMode_PWM-PWM\ Generation4\ CH4=TIM_OCMODE_PWM1
TIM3.OCPolarity_4=TIM_OCPOLARITY_HIGH
TIM3.Period=20000
TIM3.Prescaler=80-1
TIM3.Pulse-PWM\ Generation4\ CH4=0
TIM3.TIM_MasterOutputTrigger=TIM_TRGO_RESET
TIM3.TIM_MasterSlaveMode=TIM_MASTERSLAVEMODE_DISABLE
UART5.AutoBaudRateEnableParam=UART_ADVFEATURE_AUTOBAUDRATE_DISABLE
UART5.BaudRate=100000
UART5.ClockPrescaler=PRESCALER_DIV1
UART5.DMADisableonRxErrorParam=UART_ADVFEATURE_DMA_ENABLEONRXERROR
UART5.DataInvertParam=UART_ADVFEATURE_DATAINV_DISABLE
UART5.FIFOMode=FIFOMODE_DISABLE
UART5.MSBFirstParam=UART_ADVFEATURE_MSBFIRST_DISABLE
UART5.Mode=MODE_TX_RX
UART5.OneBitSampling=UART_ONE_BIT_SAMPLE_DISABLE
UART5.OverSampling=UART_OVERSAMPLING_16
UART5.OverrunDisableParam=UART_ADVFEATURE_OVERRUN_ENABLE
UART5.Parity=PARITY_EVEN
UART5.RXFIFOThreshold=RXFIFO_THRESHOLD_1EIGHTHFULL
UART5.RxPinLevelInvertParam=UART_ADVFEATURE_RXINV_DISABLE
UART5.StopBits=UART_STOPBITS_2
UART5.SwapParam=UART_ADVFEATURE_SWAP_DISABLE
UART5.TXFIFOThreshold=TXFIFO_THRESHOLD_1EIGHTHFULL
UART5.TxPinLevelInvertParam=UART_ADVFEATURE_TXINV_DISABLE
UART5.WordLength=WORDLENGTH_9B
UART7.AutoBaudRateEnableParam=UART_ADVFEATURE_AUTOBAUDRATE_DISABLE
UART7.BaudRate=921600
UART7.ClockPrescaler=PRESCALER_DIV1
UART7.DMADisableonRxErrorParam=UART_ADVFEATURE_DMA_ENABLEONRXERROR
UART7.DataInvertParam=UART_ADVFEATURE_DATAINV_DISABLE
UART7.FIFOMode=FIFOMODE_DISABLE
UART7.MSBFirstParam=UART_ADVFEATURE_MSBFIRST_DISABLE
UART7.Mode=MODE_TX_RX
UART7.OneBitSampling=UART_ONE_BIT_SAMPLE_DISABLE
UART7.OverSampling=UART_OVERSAMPLING_16
UART7.OverrunDisableParam=UART_ADVFEATURE_OVERRUN_ENABLE
UART7.Parity=PARITY_NONE
UART7.RXFIFOThreshold=RXFIFO_THRESHOLD_1EIGHTHFULL
UART7.RxPinLevelInvertParam=UART_ADVFEATURE_RXINV_DISABLE
UART7.StopBits=UART_STOPBITS_1
UART7.SwapParam=UART_ADVFEATURE_SWAP_DISABLE
UART7.TXFIFOThreshold=TXFIFO_THRESHOLD_1EIGHTHFULL
UART7.TxPinLevelInvertParam=UART_ADVFEATURE_TXINV_DISABLE
UART7.WordLength=WORDLENGTH_8B
USART1.AutoBaudRateEnableParam=UART_ADVFEATURE_AUTOBAUDRATE_DISABLE
USART1.BaudRate=115200
USART1.ClockPrescaler=PRESCALER_DIV1
USART1.DMADisableonRxErrorParam=ADVFEATURE_DMA_ENABLEONRXERROR
USART1.DataInvertParam=ADVFEATURE_DATAINV_DISABLE
USART1.FIFOMode=FIFOMODE_DISABLE
USART1.MSBFirstParam=ADVFEATURE_MSBFIRST_DISABLE
USART1.Mode=MODE_TX_RX
USART1.OneBitSampling=UART_ONE_BIT_SAMPLE_DISABLE
USART1.OverSampling=UART_OVERSAMPLING_16
USART1.OverrunDisableParam=ADVFEATURE_OVERRUN_ENABLE
USART1.Parity=PARITY_NONE
USART1.RXFIFOThreshold=RXFIFO_THRESHOLD_1EIGHTHFULL
USART1.RxPinLevelInvertParam=ADVFEATURE_RXINV_DISABLE
USART1.StopBits=STOPBITS_1
USART1.SwapParam=ADVFEATURE_SWAP_DISABLE
USART1.TXFIFOThreshold=TXFIFO_THRESHOLD_1EIGHTHFULL
USART1.TxPinLevelInvertParam=ADVFEATURE_TXINV_DISABLE
USART1.VirtualMode-Asynchronous=VM_ASYNC
USART1.WordLength=WORDLENGTH_8B
USART10.AutoBaudRateEnableParam=UART_ADVFEATURE_AUTOBAUDRATE_DISABLE
USART10.BaudRate=921600
USART10.ClockPrescaler=PRESCALER_DIV1
USART10.DMADisableonRxErrorParam=ADVFEATURE_DMA_ENABLEONRXERROR
USART10.DataInvertParam=ADVFEATURE_DATAINV_DISABLE
USART10.FIFOMode=FIFOMODE_DISABLE
USART10.MSBFirstParam=ADVFEATURE_MSBFIRST_DISABLE
USART10.Mode=MODE_TX_RX
USART10.OneBitSampling=UART_ONE_BIT_SAMPLE_DISABLE
USART10.OverSampling=UART_OVERSAMPLING_16
USART10.OverrunDisableParam=ADVFEATURE_OVERRUN_ENABLE
USART10.Parity=PARITY_NONE
USART10.RXFIFOThreshold=RXFIFO_THRESHOLD_1EIGHTHFULL
USART10.RxPinLevelInvertParam=ADVFEATURE_RXINV_DISABLE
USART10.StopBits=STOPBITS_1
USART10.SwapParam=ADVFEATURE_SWAP_DISABLE
USART10.TXFIFOThreshold=TXFIFO_THRESHOLD_1EIGHTHFULL
USART10.TxPinLevelInvertParam=ADVFEATURE_TXINV_DISABLE
USART10.VirtualMode=VM_ASYNC
USART10.WordLength=WORDLENGTH_8B
USART2.AutoBaudRateEnableParam=UART_ADVFEATURE_AUTOBAUDRATE_DISABLE
USART2.BaudRate=921600
USART2.ClockPrescaler=PRESCALER_DIV1
USART2.DMADisableonRxErrorParam=ADVFEATURE_DMA_ENABLEONRXERROR
USART2.DataInvertParam=ADVFEATURE_DATAINV_DISABLE
USART2.FIFOMode=FIFOMODE_DISABLE
USART2.MSBFirstParam=ADVFEATURE_MSBFIRST_DISABLE
USART2.Mode=MODE_TX_RX
USART2.OneBitSampling=UART_ONE_BIT_SAMPLE_DISABLE
USART2.OverSampling=UART_OVERSAMPLING_8
USART2.OverrunDisableParam=ADVFEATURE_OVERRUN_ENABLE
USART2.Parity=PARITY_NONE
USART2.RXFIFOThreshold=RXFIFO_THRESHOLD_1EIGHTHFULL
USART2.RxPinLevelInvertParam=ADVFEATURE_RXINV_DISABLE
USART2.StopBits=STOPBITS_1
USART2.SwapParam=ADVFEATURE_SWAP_DISABLE
USART2.TXFIFOThreshold=TXFIFO_THRESHOLD_1EIGHTHFULL
USART2.TxPinLevelInvertParam=ADVFEATURE_TXINV_DISABLE
USART2.UART_DEAssertionTime=0
USART2.UART_DEDeassertionTime=0
USART2.UART_DEPolarity=UART_DE_POLARITY_HIGH
USART2.VirtualMode-Asynchronous=VM_ASYNC
USART2.VirtualMode-Hardware\ Flow\ Control\ (RS485)=VM_ASYNC
USART2.WordLength=WORDLENGTH_8B
USART3.AutoBaudRateEnableParam=UART_ADVFEATURE_AUTOBAUDRATE_DISABLE
USART3.BaudRate=921600
USART3.ClockPrescaler=PRESCALER_DIV1
USART3.DMADisableonRxErrorParam=ADVFEATURE_DMA_ENABLEONRXERROR
USART3.DataInvertParam=ADVFEATURE_DATAINV_DISABLE
USART3.FIFOMode=FIFOMODE_DISABLE
USART3.MSBFirstParam=ADVFEATURE_MSBFIRST_DISABLE
USART3.Mode=MODE_TX_RX
USART3.OneBitSampling=UART_ONE_BIT_SAMPLE_DISABLE
USART3.OverSampling=UART_OVERSAMPLING_8
USART3.OverrunDisableParam=ADVFEATURE_OVERRUN_ENABLE
USART3.Parity=PARITY_NONE
USART3.RXFIFOThreshold=RXFIFO_THRESHOLD_1EIGHTHFULL
USART3.RxPinLevelInvertParam=ADVFEATURE_RXINV_DISABLE
USART3.StopBits=STOPBITS_1
USART3.SwapParam=ADVFEATURE_SWAP_DISABLE
USART3.TXFIFOThreshold=TXFIFO_THRESHOLD_1EIGHTHFULL
USART3.TxPinLevelInvertParam=ADVFEATURE_TXINV_DISABLE
USART3.UART_DEAssertionTime=0
USART3.UART_DEDeassertionTime=0
USART3.UART_DEPolarity=UART_DE_POLARITY_HIGH
USART3.VirtualMode-Asynchronous=VM_ASYNC
USART3.VirtualMode-Hardware\ Flow\ Control\ (RS485)=VM_ASYNC
USART3.WordLength=WORDLENGTH_8B
USB_DEVICE.APP_RX_DATA_SIZE=2048
USB_DEVICE.APP_TX_DATA_SIZE=2048
USB_DEVICE.CLASS_NAME_HS=CDC
USB_DEVICE.CONFIGURATION_STRING_CDC_HS=CDC Config
USB_DEVICE.INTERFACE_STRING_CDC_HS=CDC Interface
USB_DEVICE.LANGID_STRING=1033
USB_DEVICE.MANUFACTURER_STRING=STMicroelectronics
USB_DEVICE.PID_CDC_HS=22336
USB_DEVICE.PRODUCT_STRING_CDC_HS=STM32 Virtual ComPort
USB_DEVICE.USBD_DEBUG_LEVEL=0
USB_DEVICE.USBD_LPM_ENABLED=1
USB_DEVICE.USBD_MAX_NUM_CONFIGURATION=1
USB_DEVICE.USBD_MAX_NUM_INTERFACES=1
USB_DEVICE.USBD_MAX_STR_DESC_SIZ=512
USB_DEVICE.USBD_SELF_POWERED=1
USB_DEVICE.VID=1155
USB_DEVICE.VirtualMode=Cdc
USB_DEVICE.VirtualModeHS=Cdc_HS
USB_OTG_HS.VirtualMode-Device_Only_FS=Device_Only_FS
USB_OTG_HS.dma_enable-Device_Only_FS=DISABLE
USB_OTG_HS.low_power_enable-Device_Only_FS=DISABLE
USB_OTG_HS.lpm_enable-Device_Only_FS=DISABLE
USB_OTG_HS.phy_itface-Device_Only_FS=USB_OTG_EMBEDDED_PHY
USB_OTG_HS.use_dedicated_ep1-Device_Only_FS=DISABLE
VP_ADC3_TempSens_Input.Mode=IN-TempSens
VP_ADC3_Vbat_Input.Mode=IN-Vbat
VP_ADC3_Vref_Input.Mode=IN-Vrefint
VP_FREERTOS_VS_CMSIS_V1.Mode=CMSIS_V1
VP_MEMORYMAP_VS_MEMORYMAP.Mode=CurAppReg
VP_SYS_VS_tim2.Mode=TIM2
VP_USB_DEVICE_VS_USB_DEVICE_CDC_HS.Mode=CDC_HS
board=custom

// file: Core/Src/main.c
/* USER CODE BEGIN Header */
/**
  ******************************************************************************
  * @file           : main.c
  * @brief          : Main program body
  ******************************************************************************
  * @attention
  *
  * Copyright (c) 2025 STMicroelectronics.
  * All rights reserved.
  *
  * This software is licensed under terms that can be found in the LICENSE file
  * in the root directory of this software component.
  * If no LICENSE file comes with this software, it is provided AS-IS.
  *
  ******************************************************************************
  */
/* USER CODE END Header */
#include "main.h"
#include "cmsis_os.h"
#include "adc.h"
#include "dma.h"
#include "fdcan.h"
#include "spi.h"
#include "tim.h"
#include "usart.h"
#include "usb_device.h"
#include "gpio.h"

/* USER CODE BEGIN Includes */
#include "sum_init.h"
/* USER CODE END Includes */

void SystemClock_Config(void);
void PeriphCommonClock_Config(void);
static void MPU_Config(void);
void MX_FREERTOS_Init(void);

int main(void)
{

  /* MPU Configuration--------------------------------------------------------*/
  MPU_Config();

  /* MCU Configuration--------------------------------------------------------*/

  /* Reset of all peripherals, Initializes the Flash interface and the Systick. */
  HAL_Init();

  /* Configure the system clock */
  SystemClock_Config();

  /* Configure the peripherals common clocks */
  PeriphCommonClock_Config();

  /* Initialize all configured peripherals */
  MX_GPIO_Init();
  MX_DMA_Init();
  MX_FDCAN1_Init();
  MX_FDCAN2_Init();
  MX_UART5_Init();
  MX_SPI2_Init();
  MX_TIM3_Init();
  MX_UART7_Init();
  MX_USART1_UART_Init();
  MX_USART2_UART_Init();
  MX_USART3_UART_Init();
  MX_USART10_UART_Init();
  MX_FDCAN3_Init();
  MX_ADC3_Init();
  MX_ADC1_Init();
  /* USER CODE BEGIN 2 */
  Sum_Init();
  /* USER CODE END 2 */

  /* Call init function for freertos objects (in cmsis_os2.c) */
  MX_FREERTOS_Init();

  /* Start scheduler */
  osKernelStart();

  /* We should never get here as control is now taken by the scheduler */

  /* Infinite loop */
  while (1)
  {

  }
}

void SystemClock_Config(void)
{
  RCC_OscInitTypeDef RCC_OscInitStruct = {0};
  RCC_ClkInitTypeDef RCC_ClkInitStruct = {0};

  /** Supply configuration update enable
  */
  HAL_PWREx_ConfigSupply(PWR_LDO_SUPPLY);

  /** Configure the main internal regulator output voltage
  */
  __HAL_PWR_VOLTAGESCALING_CONFIG(PWR_REGULATOR_VOLTAGE_SCALE0);

  while(!__HAL_PWR_GET_FLAG(PWR_FLAG_VOSRDY)) {}

  /** Initializes the RCC Oscillators according to the specified parameters
  * in the RCC_OscInitTypeDef structure.
  */
  RCC_OscInitStruct.OscillatorType = RCC_OSCILLATORTYPE_HSE;
  RCC_OscInitStruct.HSEState = RCC_HSE_ON;
  RCC_OscInitStruct.PLL.PLLState = RCC_PLL_ON;
  RCC_OscInitStruct.PLL.PLLSource = RCC_PLLSOURCE_HSE;
  RCC_OscInitStruct.PLL.PLLM = 2;
  RCC_OscInitStruct.PLL.PLLN = 40;
  RCC_OscInitStruct.PLL.PLLP = 1;
  RCC_OscInitStruct.PLL.PLLQ = 4;
  RCC_OscInitStruct.PLL.PLLR = 2;
  RCC_OscInitStruct.PLL.PLLRGE = RCC_PLL1VCIRANGE_3;
  RCC_OscInitStruct.PLL.PLLVCOSEL = RCC_PLL1VCOWIDE;
  RCC_OscInitStruct.PLL.PLLFRACN = 0;
  if (HAL_RCC_OscConfig(&RCC_OscInitStruct) != HAL_OK)
  {
    Error_Handler();
  }

  /** Initializes the CPU, AHB and APB buses clocks
  */
  RCC_ClkInitStruct.ClockType = RCC_CLOCKTYPE_HCLK|RCC_CLOCKTYPE_SYSCLK
                              |RCC_CLOCKTYPE_PCLK1|RCC_CLOCKTYPE_PCLK2
                              |RCC_CLOCKTYPE_D3PCLK1|RCC_CLOCKTYPE_D1PCLK1;
  RCC_ClkInitStruct.SYSCLKSource = RCC_SYSCLKSOURCE_PLLCLK;
  RCC_ClkInitStruct.SYSCLKDivider = RCC_SYSCLK_DIV1;
  RCC_ClkInitStruct.AHBCLKDivider = RCC_HCLK_DIV2;
  RCC_ClkInitStruct.APB3CLKDivider = RCC_APB3_DIV2;
  RCC_ClkInitStruct.APB1CLKDivider = RCC_APB1_DIV2;
  RCC_ClkInitStruct.APB2CLKDivider = RCC_APB2_DIV2;
  RCC_ClkInitStruct.APB4CLKDivider = RCC_APB4_DIV2;

  if (HAL_RCC_ClockConfig(&RCC_ClkInitStruct, FLASH_LATENCY_3) != HAL_OK)
  {
    Error_Handler();
  }
}

void PeriphCommonClock_Config(void)
{
  RCC_PeriphCLKInitTypeDef PeriphClkInitStruct = {0};

  /** Initializes the peripherals clock
  */
  PeriphClkInitStruct.PeriphClockSelection = RCC_PERIPHCLK_ADC;
  PeriphClkInitStruct.PLL2.PLL2M = 2;
  PeriphClkInitStruct.PLL2.PLL2N = 32;
  PeriphClkInitStruct.PLL2.PLL2P = 4;
  PeriphClkInitStruct.PLL2.PLL2Q = 2;
  PeriphClkInitStruct.PLL2.PLL2R = 2;
  PeriphClkInitStruct.PLL2.PLL2RGE = RCC_PLL2VCIRANGE_3;
  PeriphClkInitStruct.PLL2.PLL2VCOSEL = RCC_PLL2VCOWIDE;
  PeriphClkInitStruct.PLL2.PLL2FRACN = 0;
  PeriphClkInitStruct.AdcClockSelection = RCC_ADCCLKSOURCE_PLL2;
  if (HAL_RCCEx_PeriphCLKConfig(&PeriphClkInitStruct) != HAL_OK)
  {
    Error_Handler();
  }
}

 /* MPU Configuration */

void MPU_Config(void)
{
  MPU_Region_InitTypeDef MPU_InitStruct = {0};

  /* Disables the MPU */
  HAL_MPU_Disable();

  /** Initializes and configures the Region and the memory to be protected
  */
  MPU_InitStruct.Enable = MPU_REGION_ENABLE;
  MPU_InitStruct.Number = MPU_REGION_NUMBER0;
  MPU_InitStruct.BaseAddress = 0x0;
  MPU_InitStruct.Size = MPU_REGION_SIZE_4GB;
  MPU_InitStruct.SubRegionDisable = 0x87;
  MPU_InitStruct.TypeExtField = MPU_TEX_LEVEL0;
  MPU_InitStruct.AccessPermission = MPU_REGION_NO_ACCESS;
  MPU_InitStruct.DisableExec = MPU_INSTRUCTION_ACCESS_DISABLE;
  MPU_InitStruct.IsShareable = MPU_ACCESS_SHAREABLE;
  MPU_InitStruct.IsCacheable = MPU_ACCESS_NOT_CACHEABLE;
  MPU_InitStruct.IsBufferable = MPU_ACCESS_NOT_BUFFERABLE;

  HAL_MPU_ConfigRegion(&MPU_InitStruct);
  /* Enables the MPU */
  HAL_MPU_Enable(MPU_PRIVILEGED_DEFAULT);

}

void HAL_TIM_PeriodElapsedCallback(TIM_HandleTypeDef *htim)
{
  if (htim->Instance == TIM2)
  {
    HAL_IncTick();
  }
}

void Error_Handler(void)
{
  __disable_irq();
  while (1)
  {
  }
}

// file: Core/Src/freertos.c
/* USER CODE BEGIN Header */
/**
  ******************************************************************************
  * File Name          : freertos.c
  * Description        : Code for freertos applications
  ******************************************************************************
  * @attention
  *
  * Copyright (c) 2025 STMicroelectronics.
  * All rights reserved.
  *
  * This software is licensed under terms that can be found in the LICENSE file
  * in the root directory of this software component.
  * If no LICENSE file comes with this software, it is provided AS-IS.
  *
  ******************************************************************************
  */
/* USER CODE END Header */

#include "FreeRTOS.h"
#include "task.h"
#include "main.h"
#include "cmsis_os.h"

osThreadId Start_INS_TaskHandle;
uint32_t Start_INS_TaskBuffer[ 2048 ];
osStaticThreadDef_t Start_INS_TaskControlBlock;
osThreadId Start_Control_TaskHandle;
uint32_t Start_Control_TaskBuffer[ 2048 ];
osStaticThreadDef_t Start_Control_TaskControlBlock;
osThreadId Start_CAN_TaskHandle;
uint32_t Start_CAN_TaskBuffer[ 2048 ];
osStaticThreadDef_t Start_CAN_TaskControlBlock;
osThreadId Start_Detect_TaskHandle;
uint32_t Start_Detect_TaskBuffer[ 2048 ];
osStaticThreadDef_t Start_Detect_TaskControlBlock;

void INS_Task(void const * argument);
void Control_Task(void const * argument);
void CAN_Task(void const * argument);
void Detect_Task(void const * argument);

extern void MX_USB_DEVICE_Init(void);
void MX_FREERTOS_Init(void); /* (MISRA C 2004 rule 8.1) */

/* GetIdleTaskMemory prototype (linked to static allocation support) */
void vApplicationGetIdleTaskMemory( StaticTask_t **ppxIdleTaskTCBBuffer, StackType_t **ppxIdleTaskStackBuffer, uint32_t *pulIdleTaskStackSize );

/* USER CODE BEGIN GET_IDLE_TASK_MEMORY */
static StaticTask_t xIdleTaskTCBBuffer;
static StackType_t xIdleStack[configMINIMAL_STACK_SIZE];

void vApplicationGetIdleTaskMemory( StaticTask_t **ppxIdleTaskTCBBuffer, StackType_t **ppxIdleTaskStackBuffer, uint32_t *pulIdleTaskStackSize )
{
  *ppxIdleTaskTCBBuffer = &xIdleTaskTCBBuffer;
  *ppxIdleTaskStackBuffer = &xIdleStack[0];
  *pulIdleTaskStackSize = configMINIMAL_STACK_SIZE;
  /* place for user code */
}
/* USER CODE END GET_IDLE_TASK_MEMORY */

void MX_FREERTOS_Init(void) {

  /* Create the thread(s) */
  /* definition and creation of Start_INS_Task */
  osThreadStaticDef(Start_INS_Task, INS_Task, osPriorityHigh, 0, 2048, Start_INS_TaskBuffer, &Start_INS_TaskControlBlock);
  Start_INS_TaskHandle = osThreadCreate(osThread(Start_INS_Task), NULL);

  /* definition and creation of Start_Control_Task */
  osThreadStaticDef(Start_Control_Task, Control_Task, osPriorityAboveNormal, 0, 2048, Start_Control_TaskBuffer, &Start_Control_TaskControlBlock);
  Start_Control_TaskHandle = osThreadCreate(osThread(Start_Control_Task), NULL);

  /* definition and creation of Start_CAN_Task */
  osThreadStaticDef(Start_CAN_Task, CAN_Task, osPriorityNormal, 0, 2048, Start_CAN_TaskBuffer, &Start_CAN_TaskControlBlock);
  Start_CAN_TaskHandle = osThreadCreate(osThread(Start_CAN_Task), NULL);

  /* definition and creation of Start_Detect_Task */
  osThreadStaticDef(Start_Detect_Task, Detect_Task, osPriorityBelowNormal, 0, 2048, Start_Detect_TaskBuffer, &Start_Detect_TaskControlBlock);
  Start_Detect_TaskHandle = osThreadCreate(osThread(Start_Detect_Task), NULL);

}

__weak void INS_Task(void const * argument)
{
  /* init code for USB_DEVICE */
  MX_USB_DEVICE_Init();
  for(;;)
  {
    osDelay(1);
  }
}

__weak void Control_Task(void const * argument)
{
  for(;;)
  {
    osDelay(1);
  }
}

__weak void CAN_Task(void const * argument)
{
  for(;;)
  {
    osDelay(1);
  }
}

__weak void Detect_Task(void const * argument)
{
  for(;;)
  {
    osDelay(1);
  }
}
